VERSION ""

NS_ :

BS_:

BU_: XXX

BO_ 827 BRAKE_PRESS: 8 XXX
 SG_ BRAKE_PRESSURE : 43|12@0+ (1,0) [0|2047] "" XXX

BO_ 1048 STEER_MOVING: 8 XXX
 SG_ STEER_ANGLE : 48|9@0+ (1,-256) [0|255] "" XXX

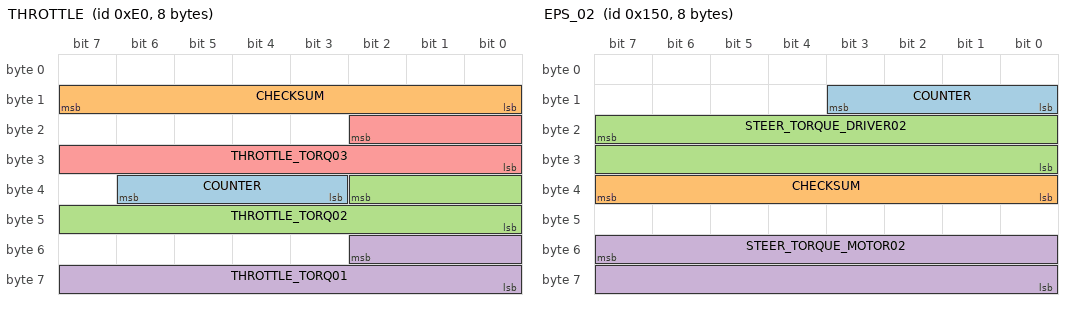
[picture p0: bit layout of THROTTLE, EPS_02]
BO_ 224 THROTTLE: 8 XXX
 SG_ COUNTER : 38|4@0+ (1,0) [0|15] "" XXX
 SG_ CHECKSUM : 8|8@1+ (1,0) [0|255] "" XXX
 SG_ THROTTLE_TORQ02 : 34|11@0+ (1,0) [0|2047] "" XXX
 SG_ THROTTLE_TORQ01 : 50|11@0+ (1,0) [0|4095] "" XXX
 SG_ THROTTLE_TORQ03 : 18|11@0+ (1,0) [0|2047] "" XXX

BO_ 242 EPS_01: 8 XXX
 SG_ STEER_ANGLE01 : 37|14@0+ (0.1,-779) [-540|540] "deg" XXX
 SG_ STEER_SPEED01 : 55|8@0+ (1,0) [0|540] "deg/sec" XXX

BO_ 336 EPS_02: 8 XXX
 SG_ COUNTER : 8|4@1+ (1,0) [0|15] "" XXX
 SG_ CHECKSUM : 32|8@1+ (1,0) [0|255] "" XXX
 SG_ STEER_TORQUE_DRIVER02 : 23|16@0- (0.2,-6548) [0|65535] "" XXX
 SG_ STEER_TORQUE_MOTOR02 : 55|16@0+ (0.4,-13096) [0|65535] "" XXX

BO_ 475 NEW_MSG_05: 8 XXX
 SG_ NEW_SIGNAL_1 : 0|8@1+ (1,0) [0|255] "" XXX

BO_ 555 SUSPENTION_ROLLING: 8 XXX
 SG_ ROLLING : 8|3@1+ (1,0) [0|255] "" XXX
 SG_ CAR_MOVING_UP : 16|4@1+ (1,0) [0|15] "" XXX

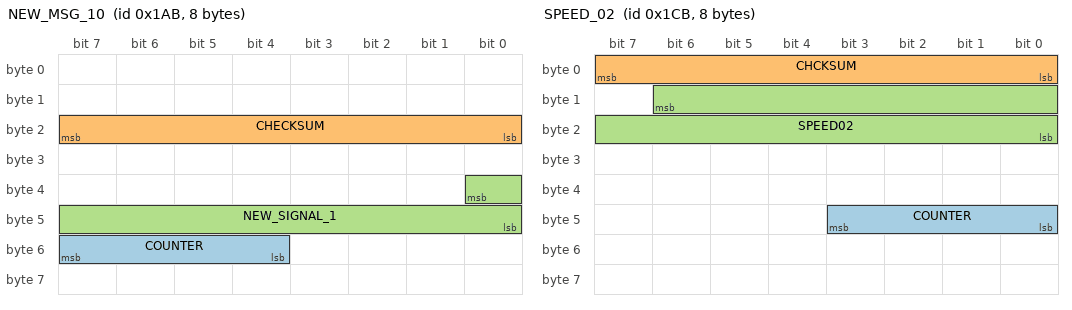
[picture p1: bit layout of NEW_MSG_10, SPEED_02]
BO_ 427 NEW_MSG_10: 8 XXX
 SG_ COUNTER : 55|4@0+ (1,0) [0|15] "" XXX
 SG_ CHECKSUM : 23|8@0+ (1,0) [0|255] "" XXX
 SG_ NEW_SIGNAL_1 : 32|9@0+ (1,0) [0|511] "" XXX

BO_ 459 SPEED_02: 8 XXX
 SG_ COUNTER : 40|4@1+ (1,0) [0|255] "" XXX
 SG_ CHCKSUM : 0|8@1+ (1,0) [0|255] "" XXX
 SG_ SPEED02 : 14|15@0+ (0.003,0) [0|65535] "" XXX

BO_ 468 LEFT_ALERT: 8 XXX
 SG_ LEFT_ALERT_1 : 1|1@0+ (1,0) [0|1] "" XXX
 SG_ LEFT_ALERT_2 : 7|1@0+ (1,0) [0|1] "" XXX

BO_ 469 RIGHT_ALERT: 8 XXX
 SG_ RIGHT_ALERT_1 : 0|1@0+ (1,0) [0|1] "" XXX
 SG_ RIGHT_ALERT_2 : 6|1@0+ (1,0) [0|1] "" XXX

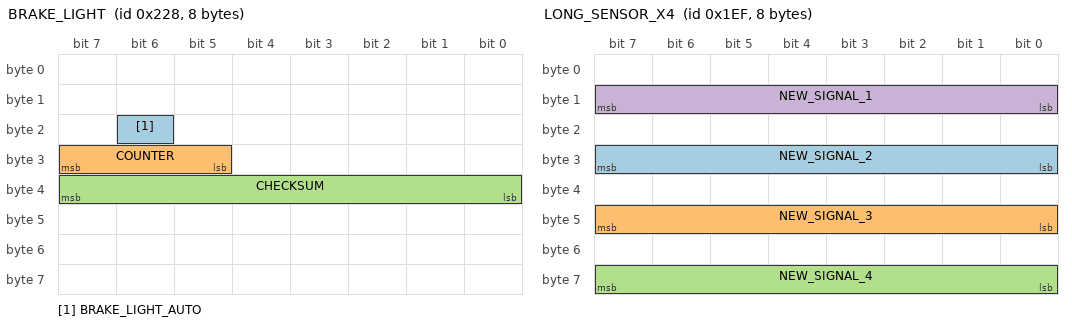
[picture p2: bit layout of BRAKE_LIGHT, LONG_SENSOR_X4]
BO_ 552 BRAKE_LIGHT: 8 XXX
 SG_ BRAKE_LIGHT_AUTO : 22|1@0+ (1,0) [0|1] "" XXX
 SG_ COUNTER : 31|3@0+ (1,0) [0|7] "" XXX
 SG_ CHECKSUM : 39|8@0+ (1,0) [0|255] "" XXX

BO_ 495 LONG_SENSOR_X4: 8 XXX
 SG_ NEW_SIGNAL_2 : 31|8@0+ (1,0) [0|15] "" XXX
 SG_ NEW_SIGNAL_3 : 40|8@1+ (1,0) [0|255] "" XXX
 SG_ NEW_SIGNAL_4 : 56|8@1+ (1,0) [0|255] "" XXX
 SG_ NEW_SIGNAL_1 : 15|8@0+ (1,0) [0|15] "" XXX

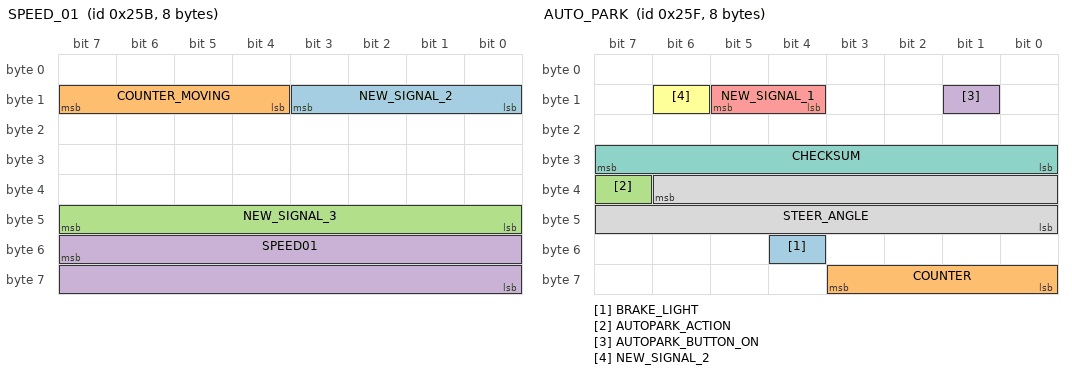
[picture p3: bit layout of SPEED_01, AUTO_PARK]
BO_ 603 SPEED_01: 8 XXX
 SG_ NEW_SIGNAL_2 : 8|4@1+ (1,0) [0|15] "" XXX
 SG_ COUNTER_MOVING : 15|4@0+ (1,0) [0|15] "" XXX
 SG_ NEW_SIGNAL_3 : 40|8@1+ (1,0) [0|255] "" XXX
 SG_ SPEED01 : 55|16@0+ (0.003,0) [0|65535] "" XXX

BO_ 607 AUTO_PARK: 8 XXX
 SG_ BRAKE_LIGHT : 52|1@0+ (1,0) [0|1] "" XXX
 SG_ COUNTER : 56|4@1+ (1,0) [0|15] "" XXX
 SG_ AUTOPARK_ACTION : 39|1@0+ (1,0) [0|1] "" XXX
 SG_ AUTOPARK_BUTTON_ON : 9|1@0+ (1,0) [0|1] "" XXX
 SG_ NEW_SIGNAL_1 : 13|2@0+ (1,0) [0|3] "" XXX
 SG_ NEW_SIGNAL_2 : 14|1@0+ (1,0) [0|1] "" XXX
 SG_ CHECKSUM : 24|8@1+ (1,0) [0|255] "" XXX
 SG_ STEER_ANGLE : 38|15@0+ (0.1,-1646) [-540|540] "" XXX

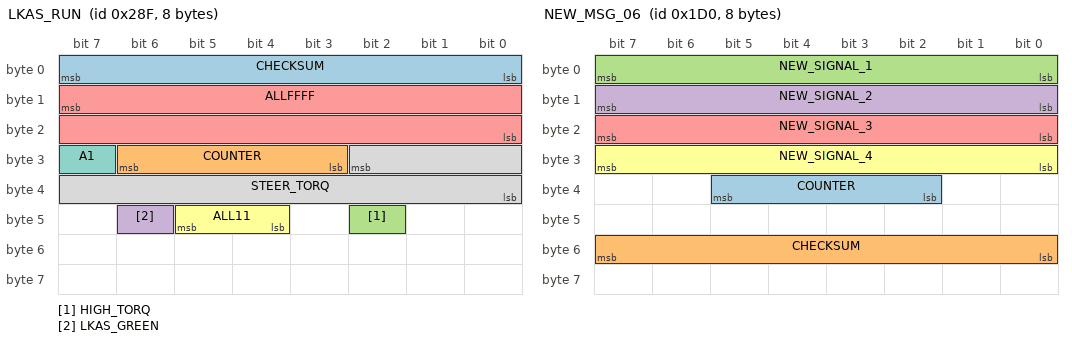
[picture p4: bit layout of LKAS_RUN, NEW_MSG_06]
BO_ 655 LKAS_RUN: 8 XXX
 SG_ CHECKSUM : 0|8@1+ (1,0) [0|255] "" XXX
 SG_ COUNTER : 30|4@0+ (1,0) [0|15] "" XXX
 SG_ HIGH_TORQ : 42|1@0+ (1,0) [0|1] "" XXX
 SG_ LKAS_GREEN : 46|1@0+ (1,0) [0|15] "" XXX
 SG_ ALLFFFF : 15|16@0+ (1,0) [0|65535] "" XXX
 SG_ ALL11 : 45|2@0+ (1,0) [0|3] "" XXX
 SG_ A1 : 31|1@0+ (1,0) [0|1] "" XXX
 SG_ STEER_TORQ : 26|11@0+ (1,-1024) [-1024|1024] "" XXX

BO_ 696 GEAR_PRND: 8 XXX
 SG_ GEAR_SHIFT : 37|6@0+ (1,0) [0|255] "" XXX

BO_ 464 NEW_MSG_06: 8 XXX
 SG_ COUNTER : 37|4@0+ (1,0) [0|15] "" XXX
 SG_ CHECKSUM : 48|8@1+ (1,0) [0|255] "" XXX
 SG_ NEW_SIGNAL_1 : 0|8@1+ (1,0) [0|255] "" XXX
 SG_ NEW_SIGNAL_2 : 8|8@1+ (1,0) [0|255] "" XXX
 SG_ NEW_SIGNAL_3 : 16|8@1+ (1,0) [0|255] "" XXX
 SG_ NEW_SIGNAL_4 : 24|8@1+ (1,0) [0|255] "" XXX

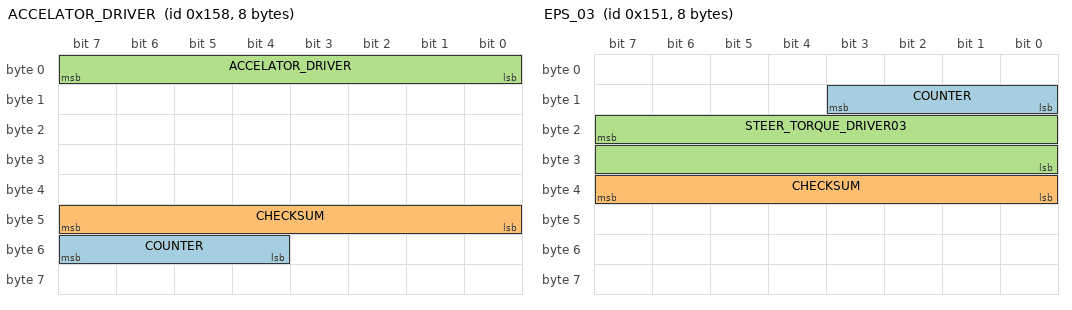
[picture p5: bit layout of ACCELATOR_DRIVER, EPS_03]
BO_ 344 ACCELATOR_DRIVER: 8 XXX
 SG_ COUNTER : 55|4@0+ (1,0) [0|15] "" XXX
 SG_ CHECKSUM : 40|8@1+ (1,0) [0|255] "" XXX
 SG_ ACCELATOR_DRIVER : 7|8@0+ (1,0) [0|255] "" XXX

BO_ 337 EPS_03: 8 XXX
 SG_ COUNTER : 8|4@1+ (1,0) [0|15] "" XXX
 SG_ CHECKSUM : 32|8@1+ (1,0) [0|255] "" XXX
 SG_ STEER_TORQUE_DRIVER03 : 23|16@0+ (0.25,-8296) [0|65535] "" XXX

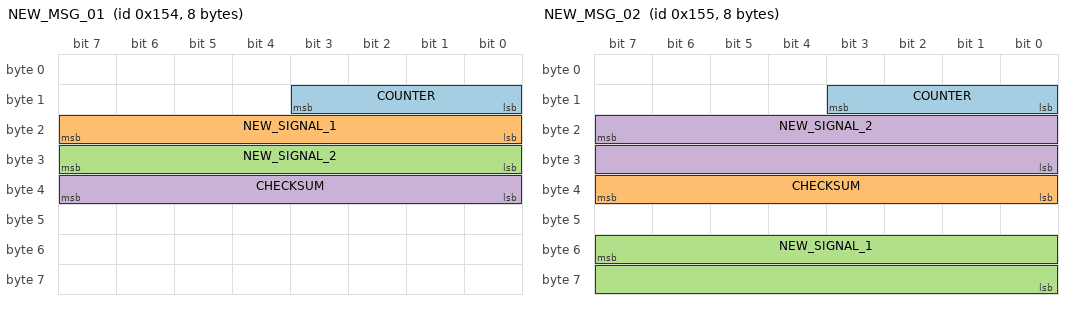
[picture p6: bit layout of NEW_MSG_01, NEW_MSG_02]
BO_ 340 NEW_MSG_01: 8 XXX
 SG_ COUNTER : 8|4@1+ (1,0) [0|15] "" XXX
 SG_ NEW_SIGNAL_1 : 23|8@0+ (1,0) [0|65535] "" XXX
 SG_ NEW_SIGNAL_2 : 24|8@1+ (1,0) [0|255] "" XXX
 SG_ CHECKSUM : 32|8@1+ (1,0) [0|255] "" XXX

BO_ 341 NEW_MSG_02: 8 XXX
 SG_ COUNTER : 8|4@1+ (1,0) [0|15] "" XXX
 SG_ CHECKSUM : 32|8@1+ (1,0) [0|255] "" XXX
 SG_ NEW_SIGNAL_1 : 55|16@0+ (1,0) [0|65535] "" XXX
 SG_ NEW_SIGNAL_2 : 23|16@0+ (1,0) [0|65535] "" XXX

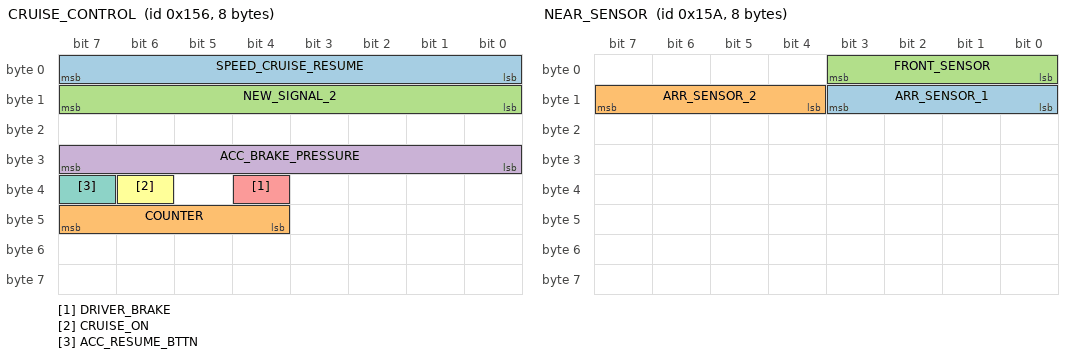
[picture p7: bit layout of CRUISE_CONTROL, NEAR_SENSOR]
BO_ 342 CRUISE_CONTROL: 8 XXX
 SG_ SPEED_CRUISE_RESUME : 7|8@0+ (3,0) [0|255] "" XXX
 SG_ COUNTER : 47|4@0+ (1,0) [0|15] "" XXX
 SG_ NEW_SIGNAL_2 : 8|8@1+ (1,0) [0|255] "" XXX
 SG_ ACC_BRAKE_PRESSURE : 31|8@0+ (1,0) [0|255] "" XXX
 SG_ DRIVER_BRAKE : 36|1@1+ (1,0) [0|1] "" XXX
 SG_ CRUISE_ON : 38|1@0+ (1,0) [0|1] "" XXX
 SG_ ACC_RESUME_BTTN : 39|1@0+ (1,0) [0|1] "" XXX

BO_ 346 NEAR_SENSOR: 8 XXX
 SG_ ARR_SENSOR_1 : 8|4@1+ (1,0) [0|255] "" XXX
 SG_ ARR_SENSOR_2 : 15|4@0+ (1,0) [0|15] "" XXX
 SG_ FRONT_SENSOR : 0|4@1+ (1,0) [0|255] "" XXX

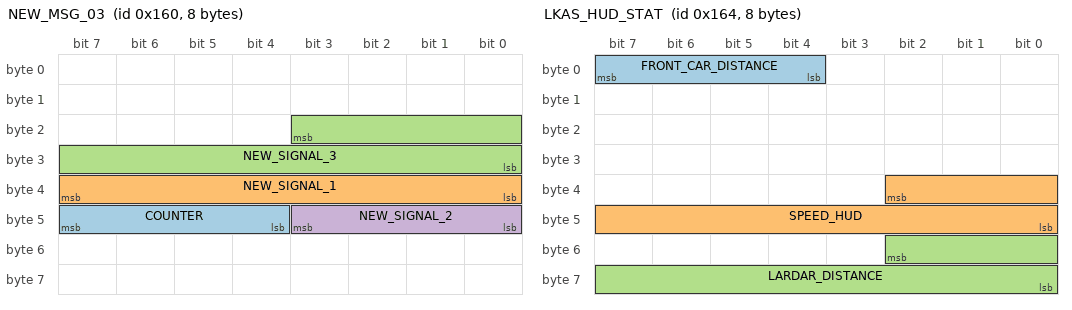
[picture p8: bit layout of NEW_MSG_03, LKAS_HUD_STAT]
BO_ 352 NEW_MSG_03: 8 XXX
 SG_ COUNTER : 47|4@0+ (1,0) [0|15] "" XXX
 SG_ NEW_SIGNAL_1 : 32|8@1+ (1,0) [0|255] "" XXX
 SG_ NEW_SIGNAL_3 : 19|12@0+ (1,0) [0|4095] "" XXX
 SG_ NEW_SIGNAL_2 : 40|4@1+ (1,0) [0|15] "" XXX

BO_ 360 NEW_MSG_04: 8 XXX

BO_ 356 LKAS_HUD_STAT: 8 XXX
 SG_ FRONT_CAR_DISTANCE : 7|4@0+ (1,0) [0|7] "" XXX
 SG_ SPEED_HUD : 34|11@0+ (1,0) [0|2047] "" XXX
 SG_ LARDAR_DISTANCE : 50|11@0+ (1,-620) [0|2047] "" XXX

BO_ 370 EPS_04: 8 XXX
 SG_ STEER_TORQUE_EPS04 : 17|10@0+ (100,-51000) [-1023|1023] "" XXX

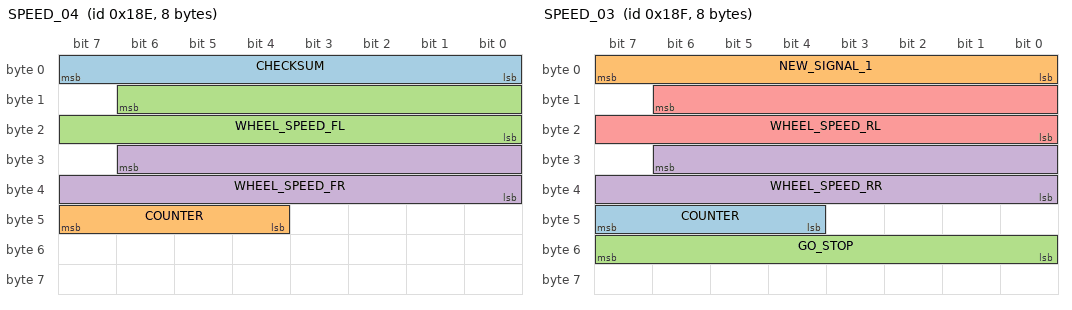
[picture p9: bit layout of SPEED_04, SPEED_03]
BO_ 398 SPEED_04: 8 XXX
 SG_ CHECKSUM : 0|8@1+ (1,0) [0|255] "" XXX
 SG_ COUNTER : 47|4@0+ (1,0) [0|15] "" XXX
 SG_ WHEEL_SPEED_FL : 14|15@0+ (0.003,0) [0|65535] "" XXX
 SG_ WHEEL_SPEED_FR : 30|15@0+ (0.003,0) [0|65535] "" XXX

BO_ 399 SPEED_03: 8 XXX
 SG_ COUNTER : 47|4@0+ (1,0) [0|15] "" XXX
 SG_ NEW_SIGNAL_1 : 0|8@1+ (1,0) [0|255] "" XXX
 SG_ GO_STOP : 48|8@1+ (1,0) [0|255] "" XXX
 SG_ WHEEL_SPEED_RR : 30|15@0+ (0.003,0) [0|32767] "" XXX
 SG_ WHEEL_SPEED_RL : 14|15@0+ (0.003,0) [0|32767] "" XXX

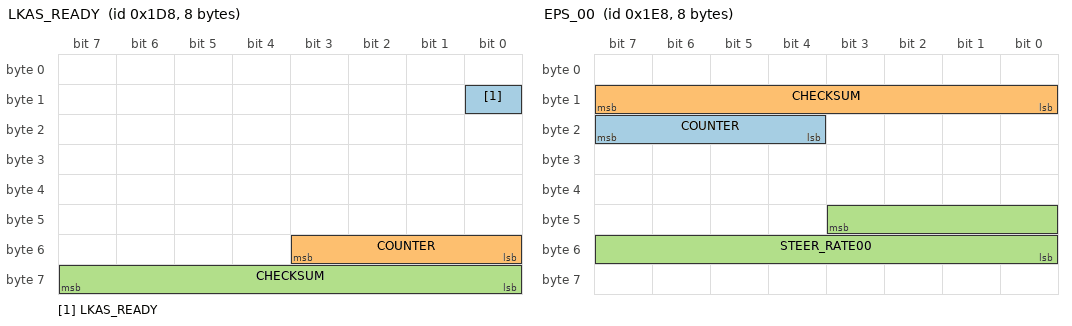
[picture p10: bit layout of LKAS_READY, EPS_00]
BO_ 472 LKAS_READY: 8 XXX
 SG_ LKAS_READY : 8|1@0+ (1,0) [0|1] "" XXX
 SG_ COUNTER : 48|4@1+ (1,0) [0|15] "" XXX
 SG_ CHECKSUM : 56|8@1+ (1,0) [0|255] "" XXX

BO_ 480 NEW_MSG_09: 8 XXX
 SG_ NEW_SIGNAL_3 : 16|1@1+ (1,0) [0|255] "" XXX
 SG_ NEW_SIGNAL_2 : 17|1@0+ (1,0) [0|1] "" XXX

BO_ 488 EPS_00: 8 XXX
 SG_ COUNTER : 23|4@0+ (1,0) [0|15] "" XXX
 SG_ CHECKSUM : 8|8@1+ (1,0) [0|255] "" XXX
 SG_ STEER_RATE00 : 43|12@0+ (20,-43160) [0|4096] "" XXX

BO_ 504 MIREROR_SEOSOR: 8 XXX
 SG_ NEW_SIGNAL_1 : 40|4@1+ (1,0) [0|15] "" XXX
 SG_ NEW_SIGNAL_2 : 56|4@1+ (1,0) [0|15] "" XXX

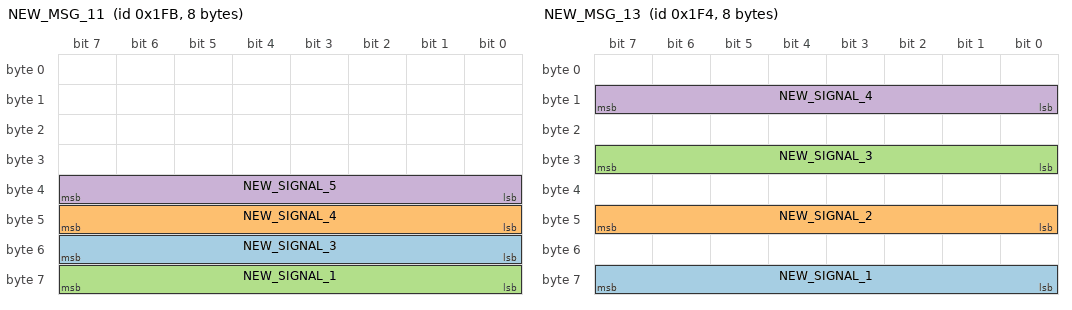
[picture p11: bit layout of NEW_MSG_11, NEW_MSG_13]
BO_ 507 NEW_MSG_11: 8 XXX
 SG_ NEW_SIGNAL_3 : 48|8@1+ (1,0) [0|255] "" XXX
 SG_ NEW_SIGNAL_4 : 40|8@1+ (1,0) [0|255] "" XXX
 SG_ NEW_SIGNAL_1 : 56|8@1+ (1,0) [0|255] "" XXX
 SG_ NEW_SIGNAL_5 : 32|8@1+ (1,0) [0|255] "" XXX

BO_ 511 NEW_MSG_12: 8 XXX
 SG_ COUNTER : 39|3@0+ (1,0) [0|7] "" XXX
 SG_ CHECKSUM : 63|8@0+ (1,0) [0|255] "" XXX

BO_ 500 NEW_MSG_13: 8 XXX
 SG_ NEW_SIGNAL_1 : 56|8@1+ (1,0) [0|255] "" XXX
 SG_ NEW_SIGNAL_2 : 40|8@1+ (1,0) [0|255] "" XXX
 SG_ NEW_SIGNAL_3 : 24|8@1+ (1,0) [0|255] "" XXX
 SG_ NEW_SIGNAL_4 : 8|8@1+ (1,0) [0|255] "" XXX

BO_ 596 NEW_MSG_14: 8 XXX

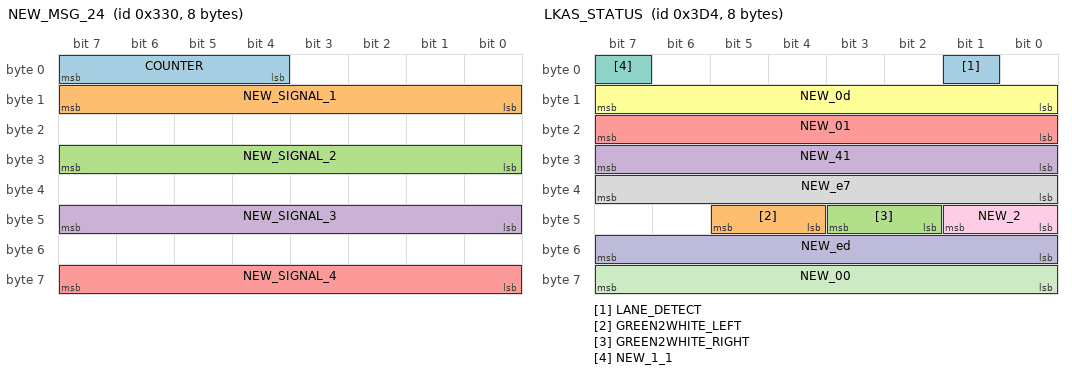
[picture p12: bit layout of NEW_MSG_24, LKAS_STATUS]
BO_ 816 NEW_MSG_24: 8 XXX
 SG_ COUNTER : 7|4@0+ (1,0) [0|15] "" XXX
 SG_ NEW_SIGNAL_1 : 8|8@1+ (1,0) [0|255] "" XXX
 SG_ NEW_SIGNAL_2 : 24|8@1+ (1,0) [0|255] "" XXX
 SG_ NEW_SIGNAL_3 : 40|8@1+ (1,0) [0|255] "" XXX
 SG_ NEW_SIGNAL_4 : 56|8@1+ (1,0) [0|255] "" XXX

BO_ 1200 NEW_MSG_45: 8 XXX

BO_ 1153 NEW_MSG_43: 8 XXX
 SG_ COUNTER : 63|4@0+ (1,0) [0|15] "" XXX

BO_ 1152 NEW_MSG_42: 8 XXX
 SG_ COUNTER : 55|4@0+ (1,0) [0|15] "" XXX

BO_ 1120 NEW_MSG_40: 8 XXX
 SG_ COUNTER_SLOW : 24|4@1+ (1,0) [0|15] "" XXX
 SG_ NEW_SIGNAL_2 : 31|4@0+ (1,0) [0|1] "" XXX

BO_ 1072 ARROUND_CAR_SENSOR: 8 XXX
 SG_ COUNTER : 40|4@1+ (1,0) [0|15] "" XXX
 SG_ ARROUND_CAR : 45|2@0+ (1,0) [0|3] "" XXX

BO_ 1060 NEW_MSG_35: 8 XXX

BO_ 1029 NEW_MSG_32: 8 XXX

BO_ 1024 NEW_MSG_28: 8 XXX

BO_ 1008 NEW_MSG_30: 8 XXX
 SG_ COUNTER : 55|4@0+ (1,0) [0|15] "" XXX
 SG_ NEW_SIGNAL_1 : 48|4@1+ (1,0) [0|15] "" XXX

BO_ 980 LKAS_STATUS: 8 XXX
 SG_ LANE_DETECT : 1|1@0+ (1,0) [0|3] "" XXX
 SG_ GREEN2WHITE_LEFT : 45|2@0+ (1,0) [0|3] "" XXX
 SG_ GREEN2WHITE_RIGHT : 42|2@1+ (1,0) [0|3] "" XXX
 SG_ NEW_41 : 31|8@0+ (1,0) [0|255] "" XXX
 SG_ NEW_01 : 23|8@0+ (1,0) [0|255] "" XXX
 SG_ NEW_0d : 15|8@0+ (1,0) [0|255] "" XXX
 SG_ NEW_1_1 : 7|1@0+ (1,0) [0|1] "" XXX
 SG_ NEW_e7 : 39|8@0+ (1,0) [0|255] "" XXX
 SG_ NEW_2 : 40|2@1+ (1,0) [0|3] "" XXX
 SG_ NEW_ed : 55|8@0+ (1,0) [0|255] "" XXX
 SG_ NEW_00 : 63|8@0+ (1,0) [0|255] "" XXX

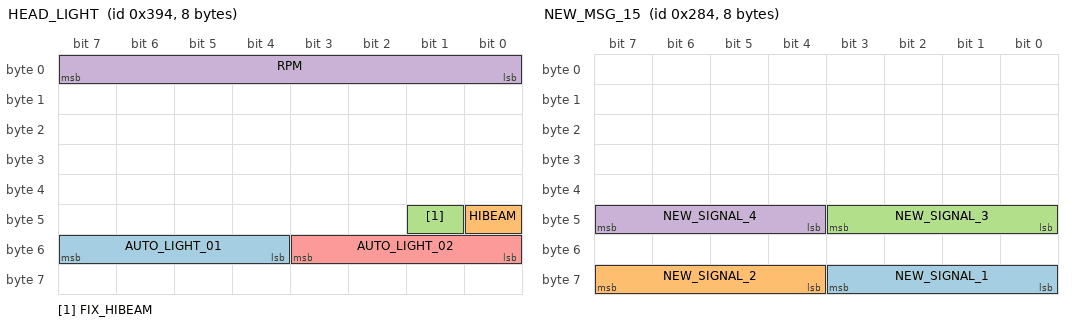
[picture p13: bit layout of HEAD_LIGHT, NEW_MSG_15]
BO_ 916 HEAD_LIGHT: 8 XXX
 SG_ AUTO_LIGHT_01 : 55|4@0+ (1,0) [0|15] "" XXX
 SG_ HIBEAM : 40|1@0+ (1,0) [0|1] "" XXX
 SG_ FIX_HIBEAM : 41|1@0+ (1,0) [0|1] "" XXX
 SG_ RPM : 0|8@1+ (1,0) [0|15] "" XXX
 SG_ AUTO_LIGHT_02 : 51|4@0+ (1,0) [0|15] "" XXX

BO_ 651 NEW_MSG_17: 8 XXX
 SG_ COUNTER : 47|4@0+ (1,0) [0|15] "" XXX

BO_ 644 NEW_MSG_15: 8 XXX
 SG_ NEW_SIGNAL_1 : 56|4@1+ (1,0) [0|15] "" XXX
 SG_ NEW_SIGNAL_2 : 63|4@0+ (1,0) [0|15] "" XXX
 SG_ NEW_SIGNAL_3 : 40|4@1+ (1,0) [0|15] "" XXX
 SG_ NEW_SIGNAL_4 : 47|4@0+ (1,0) [0|15] "" XXX

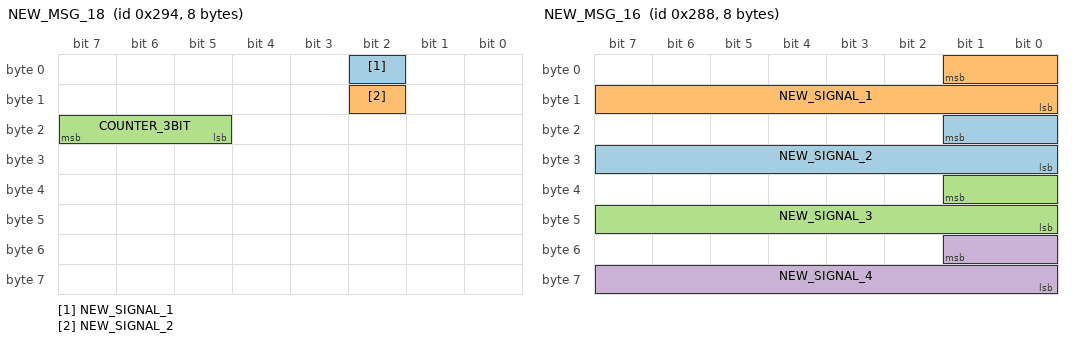
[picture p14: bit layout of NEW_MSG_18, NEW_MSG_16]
BO_ 660 NEW_MSG_18: 8 XXX
 SG_ NEW_SIGNAL_1 : 2|1@0+ (1,0) [0|1] "" XXX
 SG_ NEW_SIGNAL_2 : 10|1@0+ (1,0) [0|1] "" XXX
 SG_ COUNTER_3BIT : 23|3@0+ (1,0) [0|7] "" XXX

BO_ 648 NEW_MSG_16: 8 XXX
 SG_ NEW_SIGNAL_2 : 17|10@0+ (1,0) [0|1023] "" XXX
 SG_ NEW_SIGNAL_1 : 1|10@0+ (1,0) [0|255] "" XXX
 SG_ NEW_SIGNAL_3 : 33|10@0+ (1,0) [0|1023] "" XXX
 SG_ NEW_SIGNAL_4 : 49|10@0+ (1,0) [0|1023] "" XXX

BO_ 1168 NEW_MSG_44: 8 XXX

BO_ 692 NEW_MSG_21: 8 XXX

BO_ 720 NEW_MSG_22: 8 XXX

BO_ 1031 NEW_MSG_39: 8 XXX
 SG_ COUNTER : 0|4@1+ (1,0) [0|15] "" XXX

BO_ 1277 NEW_MSG_46: 8 XXX

BO_ 1279 NEW_MSG_47: 8 XXX

BO_ 1430 NEW_MSG_48: 8 XXX

BO_ 1438 NEW_MSG_49: 8 XXX

BO_ 1136 NEW_MSG_41: 8 XXX

BO_ 1310 NEW_MSG_38: 8 XXX

BO_ 1297 NEW_MSG_37: 8 XXX

BO_ 1056 NEW_MSG_34: 8 XXX

BO_ 1044 SEAT_BELT: 8 XXX
 SG_ SEAT_BELT_DRIVER : 3|1@0+ (1,0) [0|1] "" XXX
 SG_ SEAT_BELT_PASSEN : 51|1@0+ (1,0) [0|1] "" XXX

BO_ 1040 NEW_MSG_33: 8 XXX

BO_ 1012 NEW_MSG_31: 8 XXX

BO_ 928 NEW_MSG_29: 8 XXX

BO_ 977 NEW_MSG_27: 8 XXX

BO_ 976 BRAKE: 8 XXX
 SG_ BRAKE_AUTO : 10|1@1+ (1,0) [0|1] "" XXX
 SG_ COUNTER : 23|4@0+ (1,0) [0|15] "" XXX

BO_ 868 NEW_MSG_26: 8 XXX

BO_ 824 NEW_MSG_25: 8 XXX

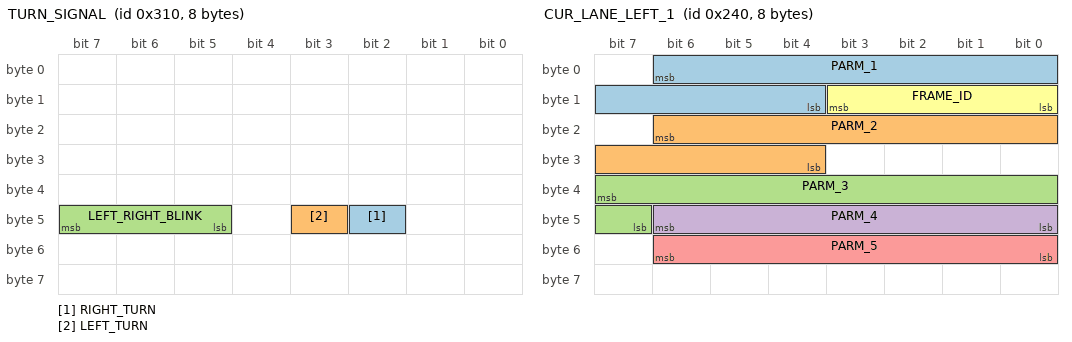
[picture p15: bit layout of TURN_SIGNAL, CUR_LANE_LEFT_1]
BO_ 784 TURN_SIGNAL: 8 XXX
 SG_ RIGHT_TURN : 42|1@0+ (1,0) [0|1] "" XXX
 SG_ LEFT_TURN : 43|1@0+ (1,0) [0|1] "" XXX
 SG_ LEFT_RIGHT_BLINK : 47|3@0+ (1,0) [0|15] "" XXX

BO_ 752 NEW_MSG_23: 8 XXX

BO_ 688 NEW_MSG_20: 8 XXX

BO_ 656 NEW_MSG_19: 8 XXX
 SG_ G_SENSOR : 17|1@0+ (1,0) [0|1] "" XXX

BO_ 576 CUR_LANE_LEFT_1: 8 XXX
 SG_ PARM_1 : 6|11@0- (1,0) [-1023|1023] "" XXX
 SG_ PARM_2 : 22|11@0- (1,0) [-1023|1023] "" XXX
 SG_ PARM_3 : 39|9@0+ (1,0) [0|511] "" XXX
 SG_ PARM_4 : 46|7@0+ (1,0) [0|127] "" XXX
 SG_ PARM_5 : 54|7@0+ (1,0) [0|127] "" XXX
 SG_ FRAME_ID : 11|4@0+ (1,0) [0|15] "" XXX

BO_ 577 CUR_LANE_LEFT_2: 8 XXX
 SG_ PARM_6 : 3|8@0+ (1,0) [0|255] "" XXX
 SG_ PARM_7 : 22|11@0- (1,0) [-1023|1023] "" XXX
 SG_ PARM_8 : 24|4@0+ (1,0) [0|15] "" XXX
 SG_ PARM_9 : 38|11@0- (1,0) [-1023|1023] "" XXX
 SG_ PARM_10 : 54|7@0- (1,0) [-63|63] "" XXX
 SG_ FRAME_ID : 7|4@0+ (1,0) [0|15] "" XXX

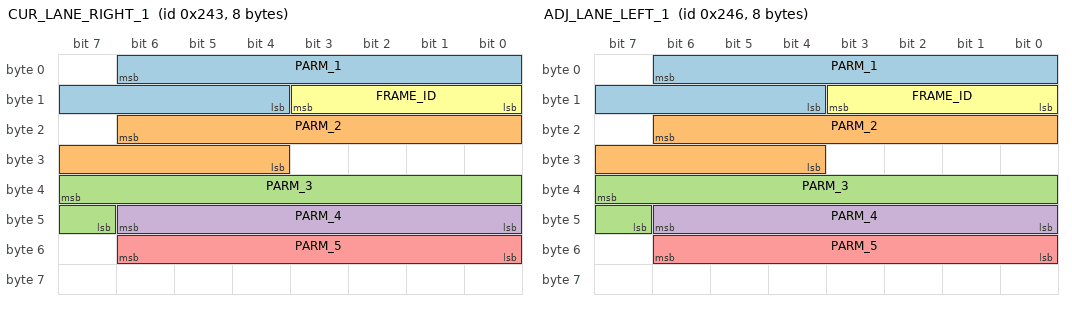
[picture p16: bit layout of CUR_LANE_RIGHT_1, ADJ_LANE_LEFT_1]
BO_ 579 CUR_LANE_RIGHT_1: 8 XXX
 SG_ PARM_1 : 6|11@0- (1,0) [-1023|1023] "" XXX
 SG_ PARM_2 : 22|11@0- (1,0) [-1023|1023] "" XXX
 SG_ PARM_3 : 39|9@0+ (1,0) [0|511] "" XXX
 SG_ PARM_4 : 46|7@0+ (1,0) [0|127] "" XXX
 SG_ PARM_5 : 54|7@0+ (1,0) [0|127] "" XXX
 SG_ FRAME_ID : 11|4@0+ (1,0) [0|15] "" XXX

BO_ 580 CUR_LANE_RIGHT_2: 8 XXX
 SG_ PARM_6 : 3|8@0+ (1,0) [0|255] "" XXX
 SG_ PARM_7 : 22|11@0- (1,0) [-1023|1023] "" XXX
 SG_ PARM_8 : 24|4@0+ (1,0) [0|15] "" XXX
 SG_ PARM_9 : 38|11@0- (1,0) [-1023|1023] "" XXX
 SG_ PARM_10 : 54|7@0- (1,0) [-63|63] "" XXX
 SG_ FRAME_ID : 7|4@0+ (1,0) [0|15] "" XXX

BO_ 582 ADJ_LANE_LEFT_1: 8 XXX
 SG_ PARM_1 : 6|11@0- (1,0) [-1023|1023] "" XXX
 SG_ PARM_2 : 22|11@0- (1,0) [-1023|1023] "" XXX
 SG_ PARM_3 : 39|9@0+ (1,0) [0|511] "" XXX
 SG_ PARM_4 : 46|7@0+ (1,0) [0|127] "" XXX
 SG_ PARM_5 : 54|7@0+ (1,0) [0|127] "" XXX
 SG_ FRAME_ID : 11|4@0+ (1,0) [0|15] "" XXX

BO_ 583 ADJ_LANE_LEFT_2: 8 XXX
 SG_ PARM_6 : 3|8@0+ (1,0) [0|255] "" XXX
 SG_ PARM_7 : 22|11@0- (1,0) [-1023|1023] "" XXX
 SG_ PARM_8 : 24|4@0+ (1,0) [0|15] "" XXX
 SG_ PARM_9 : 38|11@0- (1,0) [-1023|1023] "" XXX
 SG_ PARM_10 : 54|7@0- (1,0) [-63|63] "" XXX
 SG_ FRAME_ID : 7|4@0+ (1,0) [0|15] "" XXX

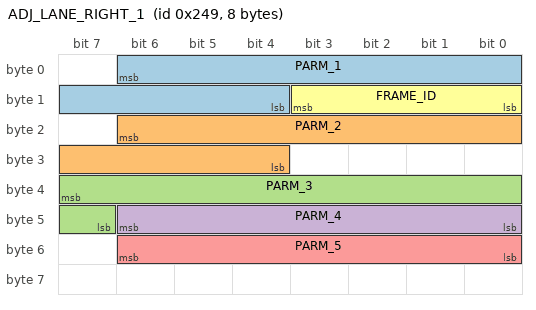
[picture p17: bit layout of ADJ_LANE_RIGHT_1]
BO_ 585 ADJ_LANE_RIGHT_1: 8 XXX
 SG_ PARM_1 : 6|11@0- (1,0) [-1023|1023] "" XXX
 SG_ PARM_2 : 22|11@0- (1,0) [-1023|1023] "" XXX
 SG_ PARM_3 : 39|9@0+ (1,0) [0|511] "" XXX
 SG_ PARM_4 : 46|7@0+ (1,0) [0|127] "" XXX
 SG_ PARM_5 : 54|7@0+ (1,0) [0|127] "" XXX
 SG_ FRAME_ID : 11|4@0+ (1,0) [0|15] "" XXX

BO_ 586 ADJ_LANE_RIGHT_2: 8 XXX
 SG_ PARM_6 : 3|8@0+ (1,0) [0|255] "" XXX
 SG_ PARM_7 : 22|11@0- (1,0) [-1023|1023] "" XXX
 SG_ PARM_8 : 24|4@0+ (1,0) [0|15] "" XXX
 SG_ PARM_9 : 38|11@0- (1,0) [-1023|1023] "" XXX
 SG_ PARM_10 : 54|7@0- (1,0) [-63|63] "" XXX
 SG_ FRAME_ID : 7|4@0+ (1,0) [0|15] "" XXX

CM_ SG_ 655 STEER_TORQ "Most sent by stock system is 1024+-230. + is left. typically changes by 2 or 3 each 0.01s";
CM_ SG_ 696 GEAR_SHIFT "PRND # P:0 R:0x09 N:0x12 D:0x1b DS:3B";
CM_ SG_ 784 LEFT_RIGHT_BLINK "left 0,1 bit, right 0,2";
CM_ SG_ 980 GREEN2WHITE_RIGHT "3: white 1:green";
CM_ SG_ 980 GREEN2WHITE_LEFT "1: green 3:white";
VAL_ 696 GEAR_SHIFT 0 "P" 9 "R" 18 "N" 27 "D";
